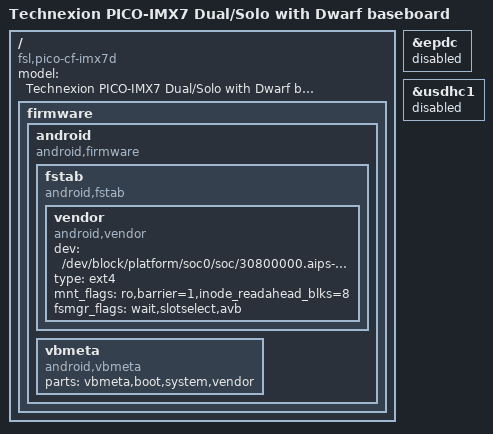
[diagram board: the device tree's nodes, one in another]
/*
 * Copyright 2016 Technexion Ltd.
 * Copyright 2017 NXP
 *
 * Author: Tapani Utriainen <tapani@technexion.com>
 *	   Richard Hu <richard.hu@technexion.com>
 *
 * This program is free software; you can redistribute it and/or modify
 * it under the terms of the GNU General Public License version 2 as
 * published by the Free Software Foundation.
 *
 */
/dts-v1/;

#include <dt-bindings/interrupt-controller/irq.h>
#include "imx7d.dtsi"
#include "imx7d-pico.dtsi"
#include "baseboard_pico_pi.dtsi"

/ {
	firmware {
		android {
			compatible = "android,firmware";
			fstab {
				compatible = "android,fstab";
				vendor {
					compatible = "android,vendor";
					dev = "/dev/block/platform/soc0/soc/30800000.aips-bus/30b60000.usdhc/by-name/vendor";
					type = "ext4";
					mnt_flags = "ro,barrier=1,inode_readahead_blks=8";
					fsmgr_flags = "wait,slotselect,avb";
				};
			};
			vbmeta {
				/* we need to use FirstStageMountVBootV2 if we enable avb */
				compatible = "android,vbmeta";
				/* parts mean the partitions which can be mounted in first stage */
				parts = "vbmeta,boot,system,vendor";
			};
		};
	};
};

/ {
	model = "Technexion PICO-IMX7 Dual/Solo with Dwarf baseboard";
	compatible = "fsl,pico-cf-imx7d", "fsl,imx7d";
};

&epdc {
	status = "disabled";
};

&usdhc1 {
	status = "disabled";
};
